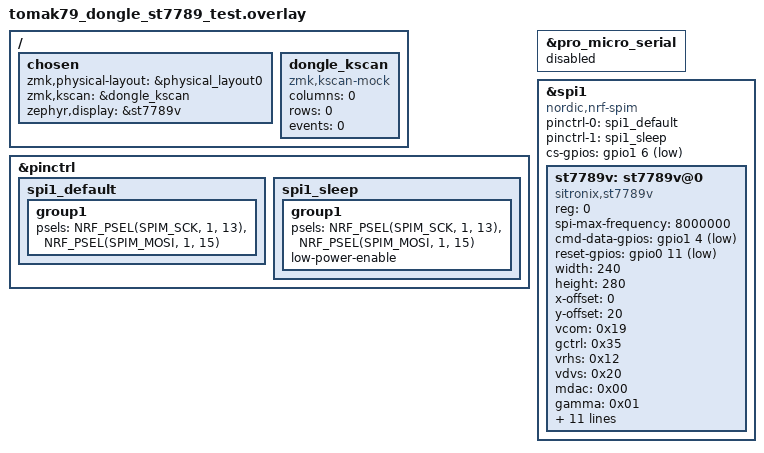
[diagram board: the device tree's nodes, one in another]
#include <behaviors.dtsi>
#include <dt-bindings/zmk/keys.h>
#include "tomak79.dtsi"

/ {
    chosen {
        zmk,physical-layout = &physical_layout0;
        zmk,kscan = &dongle_kscan;
        zephyr,display = &st7789v;
    };

    dongle_kscan: dongle_kscan {
        compatible = "zmk,kscan-mock";
        status = "okay";
        columns = <0>;
        rows = <0>;
        events = <0>;
    };
};

&pinctrl {
    spi1_default: spi1_default {
        group1 {
            psels = <NRF_PSEL(SPIM_SCK, 1, 13)>,
                    <NRF_PSEL(SPIM_MOSI, 1, 15)>;
        };
    };

    spi1_sleep: spi1_sleep {
        group1 {
            psels = <NRF_PSEL(SPIM_SCK, 1, 13)>,
                    <NRF_PSEL(SPIM_MOSI, 1, 15)>;
            low-power-enable;
        };
    };
};

&pro_micro_serial {
    status = "disabled";
};

&spi1 {
    compatible = "nordic,nrf-spim";
    status = "okay";
    pinctrl-0 = <&spi1_default>;
    pinctrl-1 = <&spi1_sleep>;
    pinctrl-names = "default", "sleep";
    cs-gpios = <&gpio1 6 GPIO_ACTIVE_LOW>;

    st7789v: st7789v@0 {
        compatible = "sitronix,st7789v";
        status = "okay";
        reg = <0>;
        spi-max-frequency = <8000000>;

        cmd-data-gpios = <&gpio1 4 GPIO_ACTIVE_LOW>;
        reset-gpios = <&gpio0 11 GPIO_ACTIVE_LOW>;

        width = <240>;
        height = <280>;

        x-offset = <0>;
        y-offset = <20>;

        vcom = <0x19>;
        gctrl = <0x35>;
        vrhs = <0x12>;
        vdvs = <0x20>;
        mdac = <0x00>;
        gamma = <0x01>;
        colmod = <0x55>;
        lcm = <0x2c>;

        porch-param = [0c 0c 00 33 33];
        cmd2en-param = [5a 69 02 01];
        pwctrl1-param = [a4 a1];

        pvgam-param = [d0 04 0d 11 13 2b 3f 54 4c 18 0d 0b 1f 23];
        nvgam-param = [d0 04 0c 11 13 2c 3f 44 51 2f 1f 1f 20 23];

        ram-param = [00 f0];
        rgb-param = [cd 08 14];
    };
};
